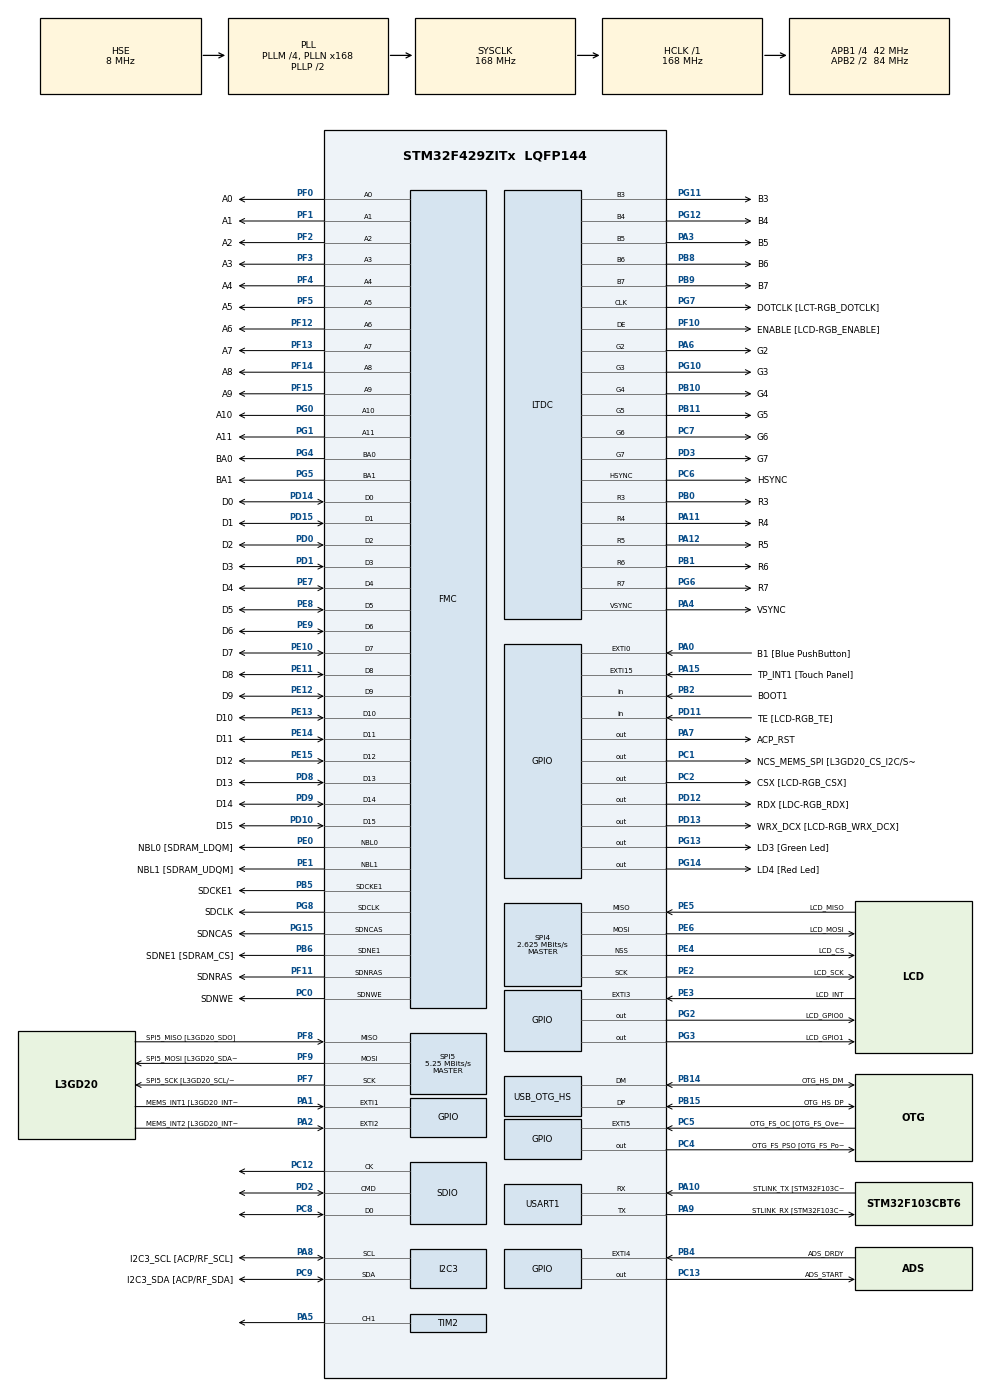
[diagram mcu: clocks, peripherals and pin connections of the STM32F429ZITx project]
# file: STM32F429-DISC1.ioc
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Dma.Request0=SDIO
Dma.Request1=SPI4_RX
Dma.Request2=SPI4_TX
Dma.SDIO.0.Direction=DMA_PERIPH_TO_MEMORY
Dma.SDIO.0.FIFOMode=DMA_FIFOMODE_ENABLE
Dma.SDIO.0.FIFOThreshold=DMA_FIFO_THRESHOLD_FULL
Dma.SDIO.0.Instance=DMA2_Stream3
Dma.SDIO.0.MemBurst=DMA_MBURST_INC4
Dma.SDIO.0.MemDataAlignment=DMA_MDATAALIGN_WORD
Dma.SDIO.0.MemInc=DMA_MINC_ENABLE
Dma.SDIO.0.Mode=DMA_PFCTRL
Dma.SDIO.0.PeriphBurst=DMA_PBURST_INC4
Dma.SDIO.0.PeriphDataAlignment=DMA_PDATAALIGN_WORD
Dma.SDIO.0.PeriphInc=DMA_PINC_DISABLE
Dma.SDIO.0.Priority=DMA_PRIORITY_VERY_HIGH
Dma.SPI4_RX.1.Direction=DMA_PERIPH_TO_MEMORY
Dma.SPI4_RX.1.FIFOMode=DMA_FIFOMODE_DISABLE
Dma.SPI4_RX.1.Instance=DMA2_Stream0
Dma.SPI4_RX.1.MemDataAlignment=DMA_MDATAALIGN_BYTE
Dma.SPI4_RX.1.MemInc=DMA_MINC_ENABLE
Dma.SPI4_RX.1.Mode=DMA_NORMAL
Dma.SPI4_RX.1.PeriphDataAlignment=DMA_PDATAALIGN_BYTE
Dma.SPI4_RX.1.PeriphInc=DMA_PINC_DISABLE
Dma.SPI4_RX.1.Priority=DMA_PRIORITY_HIGH
Dma.SPI4_TX.2.Direction=DMA_MEMORY_TO_PERIPH
Dma.SPI4_TX.2.FIFOMode=DMA_FIFOMODE_DISABLE
Dma.SPI4_TX.2.Instance=DMA2_Stream1
Dma.SPI4_TX.2.MemDataAlignment=DMA_MDATAALIGN_BYTE
Dma.SPI4_TX.2.MemInc=DMA_MINC_ENABLE
Dma.SPI4_TX.2.Mode=DMA_NORMAL
Dma.SPI4_TX.2.PeriphDataAlignment=DMA_PDATAALIGN_BYTE
Dma.SPI4_TX.2.PeriphInc=DMA_PINC_DISABLE
Dma.SPI4_TX.2.Priority=DMA_PRIORITY_LOW
FATFS.USE_DMA_CODE_SD=0
FATFS._MAX_LFN=32
FATFS._MAX_SS=4096
FATFS._USE_CHMOD=1
FATFS._USE_EXPAND=1
FMC.CASLatency1=FMC_SDRAM_CAS_LATENCY_3
FMC.ExitSelfRefreshDelay1=7
FMC.LoadToActiveDelay1=2
FMC.RCDDelay1=2
FMC.RPDelay1=2
FMC.RPDelay2=2
FMC.ReadBurst1=FMC_SDRAM_RBURST_DISABLE
FMC.ReadPipeDelay1=FMC_SDRAM_RPIPE_DELAY_1
FMC.ReadPipeDelay2=FMC_SDRAM_RPIPE_DELAY_1
FMC.RowCycleDelay1=7
FMC.RowCycleDelay2=7
FMC.SDClockPeriod1=FMC_SDRAM_CLOCK_PERIOD_2
FMC.SDClockPeriod2=FMC_SDRAM_CLOCK_PERIOD_2
FMC.SelfRefreshTime1=4
FMC.WriteRecoveryTime1=3
LTDC.ActiveH=320
LTDC.ActiveW=240
LTDC.Alpha_L0=255
LTDC.BlendingFactor1_L0=LTDC_BLENDING_FACTOR1_PAxCA
LTDC.BlendingFactor2_L0=LTDC_BLENDING_FACTOR2_PAxCA
LTDC.FBStartAdress_L0=0xD0000000
LTDC.HBP=20
LTDC.HFP=10
LTDC.HSync=10
LTDC.ImageHeight_L0=320
LTDC.ImageWidth_L0=240
LTDC.Layers=0
LTDC.PixelFormat_L0=LTDC_PIXEL_FORMAT_RGB565
LTDC.VFP=4
LTDC.VSync=2
LTDC.WindowX1_L0=240
LTDC.WindowY1_L0=320
Mcu.Family=STM32F4
Mcu.Name=STM32F429ZITx
Mcu.Package=LQFP144
NVIC.DMA2D_IRQn=true\:5\:0\:true\:false\:true\:true\:true\:true
NVIC.DMA2_Stream0_IRQn=true\:0\:0\:false\:false\:true\:false\:true\:true
NVIC.DMA2_Stream1_IRQn=true\:0\:0\:false\:false\:true\:false\:true\:true
NVIC.DMA2_Stream3_IRQn=true\:0\:0\:false\:false\:true\:false\:true\:true
NVIC.LTDC_IRQn=true\:5\:0\:true\:false\:true\:true\:true\:true
NVIC.OTG_HS_IRQn=true\:0\:0\:false\:false\:true\:true\:true\:true
NVIC.PriorityGroup=NVIC_PRIORITYGROUP_4
NVIC.SDIO_IRQn=true\:0\:0\:false\:false\:true\:true\:true\:true
NVIC.TIM1_TRG_COM_TIM11_IRQn=true\:0\:0\:false\:false\:true\:true\:true\:true
NVIC.TIM1_UP_TIM10_IRQn=true\:0\:0\:false\:false\:true\:true\:true\:true
PA0/WKUP.GPIO_Label=B1 [Blue PushButton]
PA0/WKUP.GPIO_ModeDefaultEXTI=GPIO_MODE_EVT_RISING
PA0/WKUP.GPIO_PuPd=GPIO_NOPULL
PA0/WKUP.Signal=GPXTI0
PA1.GPIO_Label=MEMS_INT1 [L3GD20_INT1]
PA1.GPIO_ModeDefaultEXTI=GPIO_MODE_EVT_RISING
PA1.GPIO_PuPd=GPIO_NOPULL
PA1.Signal=GPXTI1
PA10.GPIO_Label=STLINK_TX [STM32F103CBT6_PA2]
PA10.Mode=Asynchronous
PA10.Signal=USART1_RX
PA11.GPIO_Label=R4
PA11.GPIO_Mode=GPIO_MODE_AF_PP
PA11.GPIO_PuPd=GPIO_NOPULL
PA11.GPIO_Speed=GPIO_SPEED_FREQ_LOW
PA11.Mode=RGB565
PA11.Signal=LTDC_R4
PA12.GPIO_Label=R5
PA12.GPIO_Mode=GPIO_MODE_AF_PP
PA12.GPIO_PuPd=GPIO_NOPULL
PA12.GPIO_Speed=GPIO_SPEED_FREQ_LOW
PA12.Mode=RGB565
PA12.Signal=LTDC_R5
PA13.GPIO_Label=SWDIO
PA13.Mode=Serial_Wire
PA13.Signal=SYS_JTMS-SWDIO
PA14.GPIO_Label=SWCLK
PA14.Mode=Serial_Wire
PA14.Signal=SYS_JTCK-SWCLK
PA15.GPIO_Label=TP_INT1 [Touch Panel]
PA15.GPIO_ModeDefaultEXTI=GPIO_MODE_EVT_RISING
PA15.GPIO_PuPd=GPIO_NOPULL
PA15.Signal=GPXTI15
PA2.GPIO_Label=MEMS_INT2 [L3GD20_INT2]
PA2.GPIO_ModeDefaultEXTI=GPIO_MODE_EVT_RISING
PA2.GPIO_PuPd=GPIO_NOPULL
PA2.Signal=GPXTI2
PA3.GPIO_Label=B5
PA3.GPIO_Mode=GPIO_MODE_AF_PP
PA3.GPIO_PuPd=GPIO_NOPULL
PA3.GPIO_Speed=GPIO_SPEED_FREQ_LOW
PA3.Mode=RGB565
PA3.Signal=LTDC_B5
PA4.GPIO_Label=VSYNC
PA4.GPIO_Mode=GPIO_MODE_AF_PP
PA4.GPIO_PuPd=GPIO_NOPULL
PA4.GPIO_Speed=GPIO_SPEED_FREQ_LOW
PA4.Mode=RGB565
PA4.Signal=LTDC_VSYNC
PA5.Signal=S_TIM2_CH1_ETR
PA6.GPIO_Label=G2
PA6.GPIO_Mode=GPIO_MODE_AF_PP
PA6.GPIO_PuPd=GPIO_NOPULL
PA6.GPIO_Speed=GPIO_SPEED_FREQ_LOW
PA6.Mode=RGB565
PA6.Signal=LTDC_G2
PA7.GPIO_Label=ACP_RST
PA7.GPIO_Mode=GPIO_MODE_OUTPUT_PP
PA7.GPIO_PuPd=GPIO_NOPULL
PA7.GPIO_Speed=GPIO_SPEED_FREQ_LOW
PA7.Signal=GPIO_Output
PA8.GPIO_Label=I2C3_SCL [ACP/RF_SCL]
PA8.GPIO_Mode=GPIO_MODE_AF_OD
PA8.GPIO_Pu=GPIO_PULLUP
PA8.GPIO_PuPd=GPIO_NOPULL
PA8.GPIO_Speed=GPIO_SPEED_FREQ_LOW
PA8.Mode=I2C
PA8.Signal=I2C3_SCL
PA9.GPIO_Label=STLINK_RX [STM32F103CBT6_PA3]
PA9.Mode=Asynchronous
PA9.Signal=USART1_TX
PB0.GPIO_Label=R3
PB0.GPIO_Mode=GPIO_MODE_AF_PP
PB0.GPIO_PuPd=GPIO_NOPULL
PB0.GPIO_Speed=GPIO_SPEED_FREQ_LOW
PB0.Mode=RGB565
PB0.Signal=LTDC_R3
PB1.GPIO_Label=R6
PB1.GPIO_Mode=GPIO_MODE_AF_PP
PB1.GPIO_PuPd=GPIO_NOPULL
PB1.GPIO_Speed=GPIO_SPEED_FREQ_LOW
PB1.Mode=RGB565
PB1.Signal=LTDC_R6
PB10.GPIO_Label=G4
PB10.GPIO_Mode=GPIO_MODE_AF_PP
PB10.GPIO_PuPd=GPIO_NOPULL
PB10.GPIO_Speed=GPIO_SPEED_FREQ_LOW
PB10.Mode=RGB565
PB10.Signal=LTDC_G4
PB11.GPIO_Label=G5
PB11.GPIO_Mode=GPIO_MODE_AF_PP
PB11.GPIO_PuPd=GPIO_NOPULL
PB11.GPIO_Speed=GPIO_SPEED_FREQ_LOW
PB11.Mode=RGB565
PB11.Signal=LTDC_G5
PB12.GPIO_Label=OTG_HS_ID
PB12.GPIO_Mode=GPIO_MODE_AF_PP
PB12.GPIO_PuPd=GPIO_NOPULL
PB12.GPIO_Speed=GPIO_SPEED_FREQ_LOW
PB12.Signal=USB_OTG_HS_ID
PB13.GPIO_Label=VBUS_HS
PB13.GPIO_Mode=GPIO_MODE_INPUT
PB13.GPIO_PuPd=GPIO_NOPULL
PB13.Signal=USB_OTG_HS_VBUS
PB14.GPIO_Label=OTG_HS_DM
PB14.GPIO_Mode=GPIO_MODE_AF_PP
PB14.GPIO_PuPd=GPIO_NOPULL
PB14.GPIO_Speed=GPIO_SPEED_FREQ_LOW
PB14.Mode=Device_Only_FS
PB14.Signal=USB_OTG_HS_DM
PB15.GPIO_Label=OTG_HS_DP
PB15.GPIO_Mode=GPIO_MODE_AF_PP
PB15.GPIO_PuPd=GPIO_NOPULL
PB15.GPIO_Speed=GPIO_SPEED_FREQ_LOW
PB15.Mode=Device_Only_FS
PB15.Signal=USB_OTG_HS_DP
PB2/BOOT1.GPIO_Label=BOOT1
PB2/BOOT1.GPIO_Mode=GPIO_MODE_INPUT
PB2/BOOT1.GPIO_PuPd=GPIO_NOPULL
PB2/BOOT1.Signal=GPIO_Input
PB4.GPIO_Label=ADS_DRDY
PB4.GPIO_ModeDefaultEXTI=GPIO_MODE_IT_FALLING
PB4.GPIO_PuPd=GPIO_PULLUP
PB4.Signal=GPXTI4
PB5.GPIO_Label=SDCKE1
PB5.GPIO_Mode=GPIO_MODE_AF_PP
PB5.GPIO_PuPd=GPIO_NOPULL
PB5.GPIO_Speed=GPIO_SPEED_FREQ_VERY_HIGH
PB5.Mode=SdramChipSelect2_1
PB5.Signal=FMC_SDCKE1
PB6.GPIO_Label=SDNE1 [SDRAM_CS]
PB6.GPIO_Mode=GPIO_MODE_AF_PP
PB6.GPIO_PuPd=GPIO_NOPULL
PB6.GPIO_Speed=GPIO_SPEED_FREQ_VERY_HIGH
PB6.Mode=SdramChipSelect2_1
PB6.Signal=FMC_SDNE1
PB8.GPIO_Label=B6
PB8.GPIO_Mode=GPIO_MODE_AF_PP
PB8.GPIO_PuPd=GPIO_NOPULL
PB8.GPIO_Speed=GPIO_SPEED_FREQ_LOW
PB8.Mode=RGB565
PB8.Signal=LTDC_B6
PB9.GPIO_Label=B7
PB9.GPIO_Mode=GPIO_MODE_AF_PP
PB9.GPIO_PuPd=GPIO_NOPULL
PB9.GPIO_Speed=GPIO_SPEED_FREQ_LOW
PB9.Mode=RGB565
PB9.Signal=LTDC_B7
PC0.GPIO_Label=SDNWE
PC0.GPIO_Mode=GPIO_MODE_AF_PP
PC0.GPIO_PuPd=GPIO_NOPULL
PC0.GPIO_Speed=GPIO_SPEED_FREQ_VERY_HIGH
PC0.Signal=FMC_SDNWE
PC1.GPIO_Label=NCS_MEMS_SPI [L3GD20_CS_I2C/SPI]
PC1.GPIO_Mode=GPIO_MODE_OUTPUT_PP
PC1.GPIO_PuPd=GPIO_NOPULL
PC1.GPIO_Speed=GPIO_SPEED_FREQ_LOW
PC1.Signal=GPIO_Output
PC10.GPIO_Label=R2
PC10.GPIO_Mode=GPIO_MODE_AF_PP
PC10.GPIO_PuPd=GPIO_NOPULL
PC10.GPIO_Speed=GPIO_SPEED_FREQ_LOW
PC10.Signal=LTDC_R2
PC12.Mode=SD_1_bit
PC12.Signal=SDIO_CK
PC13.GPIO_Label=ADS_START
PC13.GPIO_Speed=GPIO_SPEED_FREQ_LOW
PC13.Signal=GPIO_Output
PC14/OSC32_IN.GPIO_Label=PC14-OSC32_IN
PC14/OSC32_IN.Mode=LSE-External-Oscillator
PC14/OSC32_IN.Signal=RCC_OSC32_IN
PC15/OSC32_OUT.GPIO_Label=PC15-OSC32_OUT
PC15/OSC32_OUT.Mode=LSE-External-Oscillator
PC15/OSC32_OUT.Signal=RCC_OSC32_OUT
PC2.GPIO_Label=CSX [LCD-RGB_CSX]
PC2.GPIO_Mode=GPIO_MODE_OUTPUT_PP
PC2.GPIO_PuPd=GPIO_NOPULL
PC2.GPIO_Speed=GPIO_SPEED_FREQ_LOW
PC2.Signal=GPIO_Output
PC4.GPIO_Label=OTG_FS_PSO [OTG_FS_PowerSwitchOn]
PC4.GPIO_Mode=GPIO_MODE_OUTPUT_PP
PC4.GPIO_PuPd=GPIO_NOPULL
PC4.GPIO_Speed=GPIO_SPEED_FREQ_LOW
PC4.Signal=GPIO_Output
PC5.GPIO_Label=OTG_FS_OC [OTG_FS_OverCurrent]
PC5.GPIO_ModeDefaultEXTI=GPIO_MODE_EVT_RISING
PC5.Signal=GPXTI5
PC6.GPIO_Label=HSYNC
PC6.GPIO_Mode=GPIO_MODE_AF_PP
PC6.GPIO_PuPd=GPIO_NOPULL
PC6.GPIO_Speed=GPIO_SPEED_FREQ_LOW
PC6.Mode=RGB565
PC6.Signal=LTDC_HSYNC
PC7.GPIO_Label=G6
PC7.GPIO_Mode=GPIO_MODE_AF_PP
PC7.GPIO_PuPd=GPIO_NOPULL
PC7.GPIO_Speed=GPIO_SPEED_FREQ_LOW
PC7.Mode=RGB565
PC7.Signal=LTDC_G6
PC8.Mode=SD_1_bit
PC8.Signal=SDIO_D0
PC9.GPIO_Label=I2C3_SDA [ACP/RF_SDA]
PC9.GPIO_Mode=GPIO_MODE_AF_OD
PC9.GPIO_Pu=GPIO_PULLUP
PC9.GPIO_PuPd=GPIO_NOPULL
PC9.GPIO_Speed=GPIO_SPEED_FREQ_LOW
PC9.Mode=I2C
PC9.Signal=I2C3_SDA
PD0.GPIO_Label=D2
PD0.GPIO_Mode=GPIO_MODE_AF_PP
PD0.GPIO_PuPd=GPIO_NOPULL
PD0.GPIO_Speed=GPIO_SPEED_FREQ_VERY_HIGH
PD0.Signal=FMC_D2_DA2
PD1.GPIO_Label=D3
PD1.GPIO_Mode=GPIO_MODE_AF_PP
PD1.GPIO_PuPd=GPIO_NOPULL
PD1.GPIO_Speed=GPIO_SPEED_FREQ_VERY_HIGH
PD1.Signal=FMC_D3_DA3
PD10.GPIO_Label=D15
PD10.GPIO_Mode=GPIO_MODE_AF_PP
PD10.GPIO_PuPd=GPIO_NOPULL
PD10.GPIO_Speed=GPIO_SPEED_FREQ_VERY_HIGH
PD10.Signal=FMC_D15_DA15
PD11.GPIO_Label=TE [LCD-RGB_TE]
PD11.GPIO_Mode=GPIO_MODE_INPUT
PD11.GPIO_PuPd=GPIO_NOPULL
PD11.Signal=GPIO_Input
PD12.GPIO_Label=RDX [LDC-RGB_RDX]
PD12.GPIO_Mode=GPIO_MODE_OUTPUT_PP
PD12.GPIO_PuPd=GPIO_NOPULL
PD12.GPIO_Speed=GPIO_SPEED_FREQ_LOW
PD12.Signal=GPIO_Output
PD13.GPIO_Label=WRX_DCX [LCD-RGB_WRX_DCX]
PD13.GPIO_Mode=GPIO_MODE_OUTPUT_PP
PD13.GPIO_PuPd=GPIO_NOPULL
PD13.GPIO_Speed=GPIO_SPEED_FREQ_LOW
PD13.Signal=GPIO_Output
PD14.GPIO_Label=D0
PD14.GPIO_Mode=GPIO_MODE_AF_PP
PD14.GPIO_PuPd=GPIO_NOPULL
PD14.GPIO_Speed=GPIO_SPEED_FREQ_VERY_HIGH
PD14.Signal=FMC_D0_DA0
PD15.GPIO_Label=D1
PD15.GPIO_Mode=GPIO_MODE_AF_PP
PD15.GPIO_PuPd=GPIO_NOPULL
PD15.GPIO_Speed=GPIO_SPEED_FREQ_VERY_HIGH
PD15.Signal=FMC_D1_DA1
PD2.Mode=SD_1_bit
PD2.Signal=SDIO_CMD
PD3.GPIO_Label=G7
PD3.GPIO_Mode=GPIO_MODE_AF_PP
PD3.GPIO_PuPd=GPIO_NOPULL
PD3.GPIO_Speed=GPIO_SPEED_FREQ_LOW
PD3.Mode=RGB565
PD3.Signal=LTDC_G7
PD6.GPIO_Label=B2
PD6.GPIO_Mode=GPIO_MODE_AF_PP
PD6.GPIO_PuPd=GPIO_NOPULL
PD6.GPIO_Speed=GPIO_SPEED_FREQ_LOW
PD6.Signal=LTDC_B2
PD8.GPIO_Label=D13
PD8.GPIO_Mode=GPIO_MODE_AF_PP
PD8.GPIO_PuPd=GPIO_NOPULL
PD8.GPIO_Speed=GPIO_SPEED_FREQ_VERY_HIGH
PD8.Signal=FMC_D13_DA13
PD9.GPIO_Label=D14
PD9.GPIO_Mode=GPIO_MODE_AF_PP
PD9.GPIO_PuPd=GPIO_NOPULL
PD9.GPIO_Speed=GPIO_SPEED_FREQ_VERY_HIGH
PD9.Signal=FMC_D14_DA14
PE0.GPIO_Label=NBL0 [SDRAM_LDQM]
PE0.GPIO_Mode=GPIO_MODE_AF_PP
PE0.GPIO_PuPd=GPIO_NOPULL
PE0.GPIO_Speed=GPIO_SPEED_FREQ_VERY_HIGH
PE0.Signal=FMC_NBL0
PE1.GPIO_Label=NBL1 [SDRAM_UDQM]
PE1.GPIO_Mode=GPIO_MODE_AF_PP
PE1.GPIO_PuPd=GPIO_NOPULL
PE1.GPIO_Speed=GPIO_SPEED_FREQ_VERY_HIGH
PE1.Signal=FMC_NBL1
PE10.GPIO_Label=D7
PE10.GPIO_Mode=GPIO_MODE_AF_PP
PE10.GPIO_PuPd=GPIO_NOPULL
PE10.GPIO_Speed=GPIO_SPEED_FREQ_VERY_HIGH
PE10.Signal=FMC_D7_DA7
PE11.GPIO_Label=D8
PE11.GPIO_Mode=GPIO_MODE_AF_PP
PE11.GPIO_PuPd=GPIO_NOPULL
PE11.GPIO_Speed=GPIO_SPEED_FREQ_VERY_HIGH
PE11.Signal=FMC_D8_DA8
PE12.GPIO_Label=D9
PE12.GPIO_Mode=GPIO_MODE_AF_PP
PE12.GPIO_PuPd=GPIO_NOPULL
PE12.GPIO_Speed=GPIO_SPEED_FREQ_VERY_HIGH
PE12.Signal=FMC_D9_DA9
PE13.GPIO_Label=D10
PE13.GPIO_Mode=GPIO_MODE_AF_PP
PE13.GPIO_PuPd=GPIO_NOPULL
PE13.GPIO_Speed=GPIO_SPEED_FREQ_VERY_HIGH
PE13.Signal=FMC_D10_DA10
PE14.GPIO_Label=D11
PE14.GPIO_Mode=GPIO_MODE_AF_PP
PE14.GPIO_PuPd=GPIO_NOPULL
PE14.GPIO_Speed=GPIO_SPEED_FREQ_VERY_HIGH
PE14.Signal=FMC_D11_DA11
PE15.GPIO_Label=D12
PE15.GPIO_Mode=GPIO_MODE_AF_PP
PE15.GPIO_PuPd=GPIO_NOPULL
PE15.GPIO_Speed=GPIO_SPEED_FREQ_VERY_HIGH
PE15.Signal=FMC_D12_DA12
PE2.GPIO_Label=LCD_SCK
PE2.Mode=Full_Duplex_Master
PE2.Signal=SPI4_SCK
PE3.GPIO_Label=LCD_INT
PE3.Signal=GPXTI3
PE4.GPIO_Label=LCD_CS
PE4.Mode=NSS_Signal_Hard_Output
PE4.Signal=SPI4_NSS
PE5.GPIO_Label=LCD_MISO
PE5.Mode=Full_Duplex_Master
PE5.Signal=SPI4_MISO
PE6.GPIO_Label=LCD_MOSI
PE6.Mode=Full_Duplex_Master
PE6.Signal=SPI4_MOSI
PE7.GPIO_Label=D4
PE7.GPIO_Mode=GPIO_MODE_AF_PP
PE7.GPIO_PuPd=GPIO_NOPULL
PE7.GPIO_Speed=GPIO_SPEED_FREQ_VERY_HIGH
PE7.Signal=FMC_D4_DA4
PE8.GPIO_Label=D5
PE8.GPIO_Mode=GPIO_MODE_AF_PP
PE8.GPIO_PuPd=GPIO_NOPULL
PE8.GPIO_Speed=GPIO_SPEED_FREQ_VERY_HIGH
PE8.Signal=FMC_D5_DA5
PE9.GPIO_Label=D6
PE9.GPIO_Mode=GPIO_MODE_AF_PP
PE9.GPIO_PuPd=GPIO_NOPULL
PE9.GPIO_Speed=GPIO_SPEED_FREQ_VERY_HIGH
PE9.Signal=FMC_D6_DA6
PF0.GPIO_Label=A0
PF0.GPIO_Mode=GPIO_MODE_AF_PP
PF0.GPIO_PuPd=GPIO_NOPULL
PF0.GPIO_Speed=GPIO_SPEED_FREQ_VERY_HIGH
PF0.Signal=FMC_A0
PF1.GPIO_Label=A1
PF1.GPIO_Mode=GPIO_MODE_AF_PP
PF1.GPIO_PuPd=GPIO_NOPULL
PF1.GPIO_Speed=GPIO_SPEED_FREQ_VERY_HIGH
PF1.Signal=FMC_A1
PF10.GPIO_Label=ENABLE [LCD-RGB_ENABLE]
PF10.GPIO_Mode=GPIO_MODE_AF_PP
PF10.GPIO_PuPd=GPIO_NOPULL
PF10.GPIO_Speed=GPIO_SPEED_FREQ_LOW
PF10.Mode=RGB565
PF10.Signal=LTDC_DE
PF11.GPIO_Label=SDNRAS
PF11.GPIO_Mode=GPIO_MODE_AF_PP
PF11.GPIO_PuPd=GPIO_NOPULL
PF11.GPIO_Speed=GPIO_SPEED_FREQ_VERY_HIGH
PF11.Signal=FMC_SDNRAS
PF12.GPIO_Label=A6
PF12.GPIO_Mode=GPIO_MODE_AF_PP
PF12.GPIO_PuPd=GPIO_NOPULL
PF12.GPIO_Speed=GPIO_SPEED_FREQ_VERY_HIGH
PF12.Signal=FMC_A6
PF13.GPIO_Label=A7
PF13.GPIO_Mode=GPIO_MODE_AF_PP
PF13.GPIO_PuPd=GPIO_NOPULL
PF13.GPIO_Speed=GPIO_SPEED_FREQ_VERY_HIGH
PF13.Signal=FMC_A7
PF14.GPIO_Label=A8
PF14.GPIO_Mode=GPIO_MODE_AF_PP
PF14.GPIO_PuPd=GPIO_NOPULL
PF14.GPIO_Speed=GPIO_SPEED_FREQ_VERY_HIGH
PF14.Signal=FMC_A8
PF15.GPIO_Label=A9
PF15.GPIO_Mode=GPIO_MODE_AF_PP
PF15.GPIO_PuPd=GPIO_NOPULL
PF15.GPIO_Speed=GPIO_SPEED_FREQ_VERY_HIGH
PF15.Signal=FMC_A9
PF2.GPIO_Label=A2
PF2.GPIO_Mode=GPIO_MODE_AF_PP
PF2.GPIO_PuPd=GPIO_NOPULL
PF2.GPIO_Speed=GPIO_SPEED_FREQ_VERY_HIGH
PF2.Signal=FMC_A2
PF3.GPIO_Label=A3
PF3.GPIO_Mode=GPIO_MODE_AF_PP
PF3.GPIO_PuPd=GPIO_NOPULL
PF3.GPIO_Speed=GPIO_SPEED_FREQ_VERY_HIGH
PF3.Signal=FMC_A3
PF4.GPIO_Label=A4
PF4.GPIO_Mode=GPIO_MODE_AF_PP
PF4.GPIO_PuPd=GPIO_NOPULL
PF4.GPIO_Speed=GPIO_SPEED_FREQ_VERY_HIGH
PF4.Signal=FMC_A4
PF5.GPIO_Label=A5
PF5.GPIO_Mode=GPIO_MODE_AF_PP
PF5.GPIO_PuPd=GPIO_NOPULL
PF5.GPIO_Speed=GPIO_SPEED_FREQ_VERY_HIGH
PF5.Signal=FMC_A5
PF7.GPIO_Label=SPI5_SCK [L3GD20_SCL/SPC]
PF7.GPIO_Mode=GPIO_MODE_AF_PP
PF7.GPIO_PuPd=GPIO_NOPULL
PF7.GPIO_Speed=GPIO_SPEED_FREQ_LOW
PF7.Mode=Full_Duplex_Master
PF7.Signal=SPI5_SCK
PF8.GPIO_Label=SPI5_MISO [L3GD20_SDO]
PF8.GPIO_Mode=GPIO_MODE_AF_PP
PF8.GPIO_PuPd=GPIO_NOPULL
PF8.GPIO_Speed=GPIO_SPEED_FREQ_LOW
PF8.Mode=Full_Duplex_Master
PF8.Signal=SPI5_MISO
PF9.GPIO_Label=SPI5_MOSI [L3GD20_SDA/SDI/SDO]
PF9.GPIO_Mode=GPIO_MODE_AF_PP
PF9.GPIO_PuPd=GPIO_NOPULL
PF9.GPIO_Speed=GPIO_SPEED_FREQ_LOW
PF9.Mode=Full_Duplex_Master
PF9.Signal=SPI5_MOSI
PG0.GPIO_Label=A10
PG0.GPIO_Mode=GPIO_MODE_AF_PP
PG0.GPIO_PuPd=GPIO_NOPULL
PG0.GPIO_Speed=GPIO_SPEED_FREQ_VERY_HIGH
PG0.Signal=FMC_A10
PG1.GPIO_Label=A11
PG1.GPIO_Mode=GPIO_MODE_AF_PP
PG1.GPIO_PuPd=GPIO_NOPULL
PG1.GPIO_Speed=GPIO_SPEED_FREQ_VERY_HIGH
PG1.Signal=FMC_A11
PG10.GPIO_Label=G3
PG10.GPIO_Mode=GPIO_MODE_AF_PP
PG10.GPIO_PuPd=GPIO_NOPULL
PG10.GPIO_Speed=GPIO_SPEED_FREQ_LOW
PG10.Mode=RGB565
PG10.Signal=LTDC_G3
PG11.GPIO_Label=B3
PG11.GPIO_Mode=GPIO_MODE_AF_PP
PG11.GPIO_PuPd=GPIO_NOPULL
PG11.GPIO_Speed=GPIO_SPEED_FREQ_LOW
PG11.Mode=RGB565
PG11.Signal=LTDC_B3
PG12.GPIO_Label=B4
PG12.GPIO_Mode=GPIO_MODE_AF_PP
PG12.GPIO_PuPd=GPIO_NOPULL
PG12.GPIO_Speed=GPIO_SPEED_FREQ_LOW
PG12.Mode=RGB565
PG12.Signal=LTDC_B4
PG13.GPIO_Label=LD3 [Green Led]
PG13.GPIO_Mode=GPIO_MODE_OUTPUT_PP
PG13.GPIO_PuPd=GPIO_NOPULL
PG13.GPIO_Speed=GPIO_SPEED_FREQ_LOW
PG13.Signal=GPIO_Output
PG14.GPIO_Label=LD4 [Red Led]
PG14.GPIO_Mode=GPIO_MODE_OUTPUT_PP
PG14.GPIO_PuPd=GPIO_NOPULL
PG14.GPIO_Speed=GPIO_SPEED_FREQ_LOW
PG14.Signal=GPIO_Output
PG15.GPIO_Label=SDNCAS
PG15.GPIO_Mode=GPIO_MODE_AF_PP
PG15.GPIO_PuPd=GPIO_NOPULL
PG15.GPIO_Speed=GPIO_SPEED_FREQ_VERY_HIGH
PG15.Signal=FMC_SDNCAS
PG2.GPIO_Label=LCD_GPIO0
PG2.GPIO_ModeDefaultOutputPP=GPIO_MODE_OUTPUT_OD
PG2.GPIO_PuPd=GPIO_PULLUP
PG2.Signal=GPIO_Output
PG3.GPIO_Label=LCD_GPIO1
PG3.GPIO_ModeDefaultOutputPP=GPIO_MODE_OUTPUT_OD
PG3.GPIO_PuPd=GPIO_PULLUP
PG3.Signal=GPIO_Output
PG4.GPIO_Label=BA0
PG4.GPIO_Mode=GPIO_MODE_AF_PP
PG4.GPIO_PuPd=GPIO_NOPULL
PG4.GPIO_Speed=GPIO_SPEED_FREQ_VERY_HIGH
PG4.Signal=FMC_A14_BA0
PG5.GPIO_Label=BA1
PG5.GPIO_Mode=GPIO_MODE_AF_PP
PG5.GPIO_PuPd=GPIO_NOPULL
PG5.GPIO_Speed=GPIO_SPEED_FREQ_VERY_HIGH
PG5.Signal=FMC_A15_BA1
PG6.GPIO_Label=R7
PG6.GPIO_Mode=GPIO_MODE_AF_PP
PG6.GPIO_PuPd=GPIO_NOPULL
PG6.GPIO_Speed=GPIO_SPEED_FREQ_LOW
PG6.Mode=RGB565
PG6.Signal=LTDC_R7
PG7.GPIO_Label=DOTCLK [LCT-RGB_DOTCLK]
PG7.GPIO_Mode=GPIO_MODE_AF_PP
PG7.GPIO_PuPd=GPIO_NOPULL
PG7.GPIO_Speed=GPIO_SPEED_FREQ_LOW
PG7.Mode=RGB565
PG7.Signal=LTDC_CLK
PG8.GPIO_Label=SDCLK
PG8.GPIO_Mode=GPIO_MODE_AF_PP
PG8.GPIO_PuPd=GPIO_NOPULL
PG8.GPIO_Speed=GPIO_SPEED_FREQ_VERY_HIGH
PG8.Signal=FMC_SDCLK
PH0/OSC_IN.GPIO_Label=PH0-OSC_IN
PH0/OSC_IN.Mode=HSE-External-Oscillator
PH0/OSC_IN.Signal=RCC_OSC_IN
PH1/OSC_OUT.GPIO_Label=PH1-OSC_OUT
PH1/OSC_OUT.Mode=HSE-External-Oscillator
PH1/OSC_OUT.Signal=RCC_OSC_OUT
ProjectManager.HeapSize=0x1000
ProjectManager.StackSize=0x2000
ProjectManager.TargetToolchain=MDK-ARM V5
RCC.48MHZClocksFreq_Value=48000000
RCC.AHBFreq_Value=168000000
RCC.APB1CLKDivider=RCC_HCLK_DIV4
RCC.APB1Freq_Value=42000000
RCC.APB1TimFreq_Value=84000000
RCC.APB2CLKDivider=RCC_HCLK_DIV2
RCC.APB2Freq_Value=84000000
RCC.APB2TimFreq_Value=168000000
RCC.CortexFreq_Value=168000000
RCC.HCLKFreq_Value=168000000
RCC.HSE_VALUE=8000000
RCC.HSI_VALUE=16000000
RCC.PLLM=4
RCC.PLLN=168
RCC.PLLQ=7
RCC.PLLSAIDivR=RCC_PLLSAIDIVR_4
RCC.PLLSAIN=100
RCC.PLLSAIR=4
RCC.RCC_RTC_Clock_Source=RCC_RTCCLKSOURCE_LSE
RCC.RCC_RTC_Clock_SourceVirtual=RCC_RTCCLKSOURCE_LSE
RCC.SYSCLKFreq_VALUE=168000000
RCC.SYSCLKSource=RCC_SYSCLKSOURCE_PLLCLK
RCC.VCOOutputFreq_Value=336000000
RTC.Date=30
RTC.Format=RTC_FORMAT_BIN
RTC.Hours=9
RTC.Minutes=6
RTC.Month=RTC_MONTH_MAY
RTC.StoreOperation=RTC_STOREOPERATION_SET
RTC.WeekDay=RTC_WEEKDAY_SUNDAY
RTC.Year=22
SDIO.ClockBypass=SDIO_CLOCK_BYPASS_DISABLE
SDIO.ClockDiv=2
SDIO.HardwareFlowControl=SDIO_HARDWARE_FLOW_CONTROL_ENABLE
SH.FMC_A0.0=FMC_A0,12b-sda1
SH.FMC_A1.0=FMC_A1,12b-sda1
SH.FMC_A10.0=FMC_A10,12b-sda1
SH.FMC_A11.0=FMC_A11,12b-sda1
SH.FMC_A14_BA0.0=FMC_BA0,FourSdramBanks1
SH.FMC_A15_BA1.0=FMC_BA1,FourSdramBanks1
SH.FMC_A2.0=FMC_A2,12b-sda1
SH.FMC_A3.0=FMC_A3,12b-sda1
SH.FMC_A4.0=FMC_A4,12b-sda1
SH.FMC_A5.0=FMC_A5,12b-sda1
SH.FMC_A6.0=FMC_A6,12b-sda1
SH.FMC_A7.0=FMC_A7,12b-sda1
SH.FMC_A8.0=FMC_A8,12b-sda1
SH.FMC_A9.0=FMC_A9,12b-sda1
SH.FMC_D0_DA0.0=FMC_D0,sd-16b-d1
SH.FMC_D10_DA10.0=FMC_D10,sd-16b-d1
SH.FMC_D11_DA11.0=FMC_D11,sd-16b-d1
SH.FMC_D12_DA12.0=FMC_D12,sd-16b-d1
SH.FMC_D13_DA13.0=FMC_D13,sd-16b-d1
SH.FMC_D14_DA14.0=FMC_D14,sd-16b-d1
SH.FMC_D15_DA15.0=FMC_D15,sd-16b-d1
SH.FMC_D1_DA1.0=FMC_D1,sd-16b-d1
SH.FMC_D2_DA2.0=FMC_D2,sd-16b-d1
SH.FMC_D3_DA3.0=FMC_D3,sd-16b-d1
SH.FMC_D4_DA4.0=FMC_D4,sd-16b-d1
SH.FMC_D5_DA5.0=FMC_D5,sd-16b-d1
SH.FMC_D6_DA6.0=FMC_D6,sd-16b-d1
SH.FMC_D7_DA7.0=FMC_D7,sd-16b-d1
SH.FMC_D8_DA8.0=FMC_D8,sd-16b-d1
SH.FMC_D9_DA9.0=FMC_D9,sd-16b-d1
SH.FMC_NBL0.0=FMC_NBL0,Sd2ByteEnable1
SH.FMC_NBL1.0=FMC_NBL1,Sd2ByteEnable1
SH.FMC_SDCLK.0=FMC_SDCLK,12b-sda1
SH.FMC_SDNCAS.0=FMC_SDNCAS,12b-sda1
SH.FMC_SDNRAS.0=FMC_SDNRAS,12b-sda1
SH.FMC_SDNWE.0=FMC_SDNWE,12b-sda1
SH.S_TIM2_CH1_ETR.0=TIM2_CH1,PWM Generation1 CH1
SPI4.BaudRatePrescaler=SPI_BAUDRATEPRESCALER_32
SPI4.CLKPhase=SPI_PHASE_2EDGE
SPI4.CalculateBaudRate=2.625 MBits/s
SPI4.Direction=SPI_DIRECTION_2LINES
SPI4.Mode=SPI_MODE_MASTER
SPI4.VirtualNSS=VM_NSSHARD
SPI4.VirtualType=VM_MASTER
SPI5.BaudRatePrescaler=SPI_BAUDRATEPRESCALER_16
SPI5.CalculateBaudRate=5.25 MBits/s
SPI5.Direction=SPI_DIRECTION_2LINES
SPI5.Mode=SPI_MODE_MASTER
SPI5.VirtualType=VM_MASTER
TIM10.Period=9999
TIM10.Prescaler=16799
TIM11.Period=999
TIM11.Prescaler=16799
TIM2.Channel-PWM\ Generation1\ CH1=TIM_CHANNEL_1
TIM2.Period=3999
TIM2.Prescaler=41999
TIM2.Pulse-PWM\ Generation1\ CH1=79
USART1.VirtualMode=VM_ASYNC
USB_DEVICE.CLASS_NAME_HS=CDC
USB_DEVICE.VirtualMode-CDC_HS=Cdc
USB_DEVICE.VirtualModeHS=Cdc_HS
USB_OTG_HS.VirtualMode-Device_Only_FS=Device_Only_FS
VP_CRC_VS_CRC.Mode=CRC_Activate
VP_DMA2D_VS_DMA2D.Mode=DMA2D_Activate
VP_FATFS_VS_SDIO.Mode=SDIO
VP_RTC_VS_RTC_Activate.Mode=RTC_Enabled
VP_RTC_VS_RTC_Calendar.Mode=RTC_Calendar
VP_TIM10_VS_ClockSourceINT.Mode=Enable_Timer
VP_TIM11_VS_ClockSourceINT.Mode=Enable_Timer
VP_USB_DEVICE_VS_USB_DEVICE_CDC_HS.Mode=CDC_HS
board=STM32F429I-DISC1

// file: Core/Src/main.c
/* USER CODE BEGIN Header */
/** new test
  ******************************************************************************
  * @file           : main.c
  * @brief          : Main program body
  ******************************************************************************
  * @attention
  *
  * Copyright (c) 2022 STMicroelectronics.
  * All rights reserved.
  *
  * This software is licensed under terms that can be found in the LICENSE file
  * in the root directory of this software component.
  * If no LICENSE file comes with this software, it is provided AS-IS.
  *
  ******************************************************************************
  */
/* USER CODE END Header */
#include "main.h"
#include "crc.h"
#include "dma.h"
#include "dma2d.h"
#include "fatfs.h"
#include "i2c.h"
#include "ltdc.h"
#include "rtc.h"
#include "sdio.h"
#include "spi.h"
#include "tim.h"
#include "usart.h"
#include "usb_device.h"
#include "gpio.h"
#include "fmc.h"

/* USER CODE BEGIN Includes */
#include "stm32f429i_discovery_lcd1.h"
#include "stm32f429i_discovery_ts.h"
#include "color2.h"
#include "save.h"
#include "stlogo.h"
#include "stdio.h"
#include "string.h"
#include <stdlib.h>
#include <math.h>
#include "arm_math.h"
#include "usbd_cdc_if.h"
/* USER CODE END Includes */

/* USER CODE BEGIN PD */
#define	rd_step1 2100;
#define	rd_step2 256;
#define	rd_step3 4200;
/* USER CODE END PD */

/* USER CODE BEGIN PV */
//ADS-----------------------------
	uint8_t tx_buff1[30] ;
	uint8_t tx_buff2[28] ;//= {0,1,2,3,4,5,6,7};
	uint8_t rx_buff[28];

	uint8_t rcv_buff[28];
	uint16_t sample_counter;        //sample counter
	uint16_t n_sample = 800;        //number of sample
	uint32_t in_signal[800];			  // input signal vector
//ADS-----------------------------
RTC_TimeTypeDef currentTime;
RTC_DateTypeDef currentDate;
RTC_TimeTypeDef sTime;
RTC_DateTypeDef sDate;
 struct  stm_packet												//34byte
		{
			uint8_t start;												//start byte	(0x55)
			uint8_t stm_com;											//command : "idel=0","get_status=1","wait for charge=2","charge_OK=3","charge_NOK=4","wait for shock=5","shock_OK=6","shock_NOK=7","...
			uint8_t stm_status;	//uint16_t stm_status;									//stm board internal status
			uint16_t date_year;										// year (binary), offset=2000
			uint8_t date_month;										// month (binary)
			uint8_t date_day;											// day (binary)
			uint8_t time_hour;										// hour (binary)
			uint8_t time_minute;									// minute (binary)
			uint8_t time_second;									// second (binary)
			uint8_t stop;													//stop byte	(0xAA)
		} s1;

struct  PcPacket{
    uint8_t     start;			//start byte
		uint8_t     CommandType;     //command : "charge = 1","shock = 2 ","sync_shock = 3 ",...
    uint8_t     status;         //PC internal status
    uint8_t     year;           // year (binary), offset=2000
    uint8_t     month;          // month (binary)
    uint8_t     day;            // day (binary)
    uint8_t     hour;           // hour (binary)
    uint8_t     minute;         // minute (binary)
    uint8_t     second;         // second (binary)
    uint8_t     stop;			//stop byte
}pc,rcv;				//228byte

 extern   struct  bit_flag
		{
			uint8_t file_end;
			uint8_t file_new_create;
			uint8_t PC_DAT_RCV	;		//flag for recieve packet form pc
			uint8_t STM_DAT_STP;
			uint8_t error_handler;
			uint8_t history ;
			uint8_t download ;
			uint8_t settime ;
			uint8_t format ;
			unsigned sampling_state :1;
			unsigned data_rcv_flg	  :1;
			unsigned data_dump_flg  :1;
			unsigned data_set_flg   :1;
			unsigned spi4_strt_flg	:1;																				// priode timer flag for transmit spi4
			unsigned spi4_end_flg 	:1;																				// priode timer flag for transmit spi4
			unsigned tim10_flg 			:1;
			unsigned tim11_flg 			:1;
		} f1 ;

  uint8_t pc_buf[228];         //data recieve buffer
	uint16_t pc_buf_size;        //number of bytes recieve size
	uint8_t num_packet = 10 ;	  //number of bytes in packet for recieve data
	uint8_t stm_buf[30]={0x55,1,2,3,4,5,6,7,8,9,10,11,12,13,14,15,16,17,18,19,20,21,22,23,24,25,26,27,254,0xAA}; //sample packet with 30 byte
	uint8_t stm_buf_DSP[32];
  static uint8_t buffer[_MAX_SS]; /* a work buffer for the f_mkfs() */

extern uint8_t SET_DATA[4];          //setting data

/* USER CODE END PV */

void SystemClock_Config(void);
/* USER CODE BEGIN PFP */
void Touchscreen_Calibration (void);
void var_print(uint16_t,uint16_t,uint16_t);
void svar_print(int32_t,uint16_t,uint16_t);
void var_printH(uint16_t,uint8_t,uint8_t,uint16_t,uint16_t);
void var8_printH(uint8_t,uint8_t,uint16_t,uint16_t);
void svar_printH(int32_t,uint8_t,uint16_t,uint16_t);
void txt_printH(uint8_t *, uint8_t, uint8_t, uint16_t, uint16_t);
void disp( char, uint8_t, uint16_t, uint16_t, char, char, char, char, char, char );
void disp1( char ,char ,char ,char ,char ,char );

void rd_disk(void);
void rd_file (void);
FRESULT scan_files ( char* path );
void make_folder(void);
void w_file_name (void);
void r_file_name (void);
void cpypc_pcbuf (void);

/* USER CODE END PFP */

/* USER CODE BEGIN 0 */
extern uint8_t retSD; /* Return value for SD */
extern FATFS SDFatFS; /* File system object for SD logical drive */
extern FIL SDFile1,SDFile2; /* File object for SD */
extern char SDPath[4]; /* SD logical drive path */
  FRESULT res;                                          /* FatFs function common result code */
  uint32_t byteswritten, bytesread;                     /* File write/read counts */
  uint8_t rtext[8400];                                  /* Read File buffer */
	uint32_t icnt ;
	uint32_t diff_dat ;
	uint32_t file_size ;
	uint16_t rd_step = rd_step1;
	char NFILE[28];   		  // file name
	char SDpat[15];					// temp path
	char str_table[20] = {0x30,0x31,0x32,0x33,0x34,0x35,0x36,0x37,0x38,0x39,0x30,0x31,0x32,0x33,0x34,0x35, 0x2E,0x42,0x49,0x4E}; // " . B I N "
  char SDpat_r[15];   		// input path buffer
	char file[8];				    // temp buffer for path files array
	char file_arr[750][8];	// path files array
	char rfile[28];					//file name for read from file
	uint16_t f_cnt = 0;			// scan found files counter
//==================================================================================

static void GetPosition(void);
static void Update_ColorSize(void);
static uint32_t radius = 1;

static char mod_flag = 0;
static char wav_flag = 0;
static char bpm_flag = 0;
static char wid_flag = 0;
static char amp_flag = 0;
static char range_flag = 0;
static char tim_flag = 0;
static char r_flag = 0;

static char MODE = 0;										// mode input    ( "0" = ECG-SIM , "1" = DEFITST ,  ECG-SIM default )
static char RANGE = 1;										// range input   ( "0" = 1.5Kv , "1" = 3.0Kv ,  4kv default )
static char TIME = 0;										// time input    ( "0" = 20ms, "1" = 40ms ,  20ms default
static char AMPL = 1;										// amplitude     ( 5 mv default )
static uint8_t CURVE_TYPE = 1;							// type of curve ( qrs default )
static uint16_t BPM = 60;								// bpm					 ( 75 bpm default )
static uint16_t WIDTH = 100;							// pulse width	 ( 500 ms default )
static float R = 50;										//load resistance
/* USER CODE END 0 */

int main(void)
{

  /* MCU Configuration--------------------------------------------------------*/

  /* Reset of all peripherals, Initializes the Flash interface and the Systick. */
  HAL_Init();

  /* Configure the system clock */
  SystemClock_Config();

  /* Initialize all configured peripherals */
  MX_GPIO_Init();
  MX_CRC_Init();
  MX_DMA2D_Init();
  MX_FMC_Init();
  MX_I2C3_Init();
  MX_LTDC_Init();
  MX_SPI5_Init();
  MX_USART1_UART_Init();
  MX_RTC_Init();
  MX_SDIO_SD_Init();
  MX_FATFS_Init();
  MX_DMA_Init();
  MX_SPI4_Init();
  MX_USB_DEVICE_Init();
  MX_TIM2_Init();
  MX_TIM10_Init();
  MX_TIM11_Init();
  /* USER CODE BEGIN 2 */
  /* Initialize the LCD */
  BSP_LCD_Init();
  /* Layer2 Init */
  BSP_LCD_LayerDefaultInit(1, LCD_FRAME_BUFFER_LAYER1);
  /* Set Foreground Layer */
  BSP_LCD_SelectLayer(1);
  /* Clear the LCD */
  BSP_LCD_Clear(LCD_COLOR_WHITE);
  BSP_LCD_SetColorKeying(1, LCD_COLOR_WHITE);
  BSP_LCD_SetLayerVisible(1, DISABLE);

  /* Layer1 Init */
  BSP_LCD_LayerDefaultInit(0, LCD_FRAME_BUFFER_LAYER0);

  /* Set Foreground Layer */
  BSP_LCD_SelectLayer(0);

  /* Enable The LCD */
  BSP_LCD_DisplayOn();

  /* Clear the LCD */
  BSP_LCD_Clear(LCD_COLOR_WHITE);

  Touchscreen_Calibration();
  BSP_TS_Init(BSP_LCD_GetXSize(), BSP_LCD_GetYSize());

//-----------------------------------------------------  /* Draw Bitmap */------------------
//BSP_LCD_DrawBitmap(40, 2, (uint8_t *)arm3);
//HAL_Delay(3000);
//-----------------------------------------------------  /* Draw Bitmap */------------------

BSP_LCD_SelectLayer(0);//select on which layer we write
BSP_LCD_DisplayOn();//turn on LCD
BSP_LCD_SetFont(&Font24);
BSP_LCD_Clear(LCD_COLOR_BLUE);//clear the LCD on blue color
BSP_LCD_SetBackColor(LCD_COLOR_BLUE);//set text background color

BSP_LCD_DisplayStringAtLineH(0," TPD Demo tester");

disp ( MODE , CURVE_TYPE , BPM , WIDTH , AMPL , mod_flag , wav_flag , bpm_flag , wid_flag , amp_flag );
BSP_LCD_SetTextColor(LCD_COLOR_WHITE);//set text color
BSP_LCD_SetBackColor(LCD_COLOR_RED);//set text background color
txt_printH("SET",3,11,200,35);
  	HAL_GPIO_WritePin(GPIOG, GPIO_PIN_13, GPIO_PIN_RESET );     //led G off
  	HAL_GPIO_WritePin(GPIOG, GPIO_PIN_14, GPIO_PIN_RESET );     //led R off
		f1.file_end = 0;
	  f1.error_handler = 0;
//mSD------------------------------------------------------------------------------------------------
	HAL_RTC_GetTime(&hrtc, &currentTime, FORMAT_BIN);
	HAL_RTC_GetDate(&hrtc, &currentDate, FORMAT_BIN);
	if(f_mount(&SDFatFS, (TCHAR const*)SDPath, 0) != FR_OK)	{								//mount disk
		Error_Handler();
	}
//	BSP_LED_On(LED3);
	make_folder();																													//making folder & directory
	w_file_name();																													//create file name from date

	if (f_open(&SDFile1, NFILE, FA_CREATE_ALWAYS | FA_WRITE ) != FR_OK) {		//open file
		Error_Handler();
	}

	if (f_lseek(&SDFile1, f_size(&SDFile1))!= FR_OK)	{											//seek addres file
		Error_Handler();
	}
	f1.file_new_create = 0;
	f1.STM_DAT_STP = 0;
//mSD------------------------------------------------------------------------------------------------
  /* USER CODE END 2 */

  /* Infinite loop */
  while (1)
  {

    /* USER CODE BEGIN 3 */
	}
//ADS----------------------------------------------------------------------------
		if ( f1.sampling_state == 1 )	{
			if	( sample_counter != n_sample )	{
				if ( f1.data_rcv_flg == 1 )  {
///////// READ DATA (9 byte)
					HAL_GPIO_WritePin(GPIOE, GPIO_PIN_4, GPIO_PIN_RESET );					//CS_P	 			active
					HAL_SPI_TransmitReceive_DMA(&hspi4,tx_buff1,rcv_buff,9);				//27 byte (216 bit)	RECIEVE
					in_signal[sample_counter] = (rcv_buff[3]<<24)+(rcv_buff[4]<<16)+(rcv_buff[5]<<8);
					f1.data_rcv_flg = 0;
///////// READ DATA (9 byte)
					sample_counter++;
				}
			}
			else	{
				sample_counter = 0;
				f1.sampling_state = 0;
			}
		}
//ADS----------------------------------------------------------------------------
//mSD----------------------------------------------------------------------------new file create
	if ( (currentTime.Minutes == 0) && (currentTime.Seconds <= 10) && (f1.file_new_create == 0) )	{
		if (f_close(&SDFile1) != FR_OK )	{
			Error_Handler();
		}
		make_folder();
		w_file_name();

		if (f_open(&SDFile1, NFILE, FA_CREATE_ALWAYS | FA_WRITE ) != FR_OK) {
			Error_Handler();
		}

		if (f_lseek(&SDFile1, f_size(&SDFile1))!= FR_OK)	{
			Error_Handler();
		}
		f1.file_new_create = 1;
	}else	if ( (currentTime.Minutes == 0) && (currentTime.Seconds > 10) ) {
		f1.file_new_create = 0;
	}
//mSD----------------------------------------------------------------------------
//DSP---------------------------------------------------
//										if ( f1.data_dump_flg == 0 ) {
//												CDC_Transmit_HS(stm_buf_DSP,6);
//										}
										else	{}
//mSD write------------------------------------------------------------------
		res = f_write(&SDFile1, stm_buf_DSP, 6 , (void *)&byteswritten);
		if((byteswritten == 0) || (res != FR_OK)) {
			Error_Handler();
		}
		res = f_sync(&SDFile1);
		if( res != FR_OK )	{
			Error_Handler();
		}
//mSD write------------------------------------------------------------------

//DSP---------------------------------------------------

//RTC------------------------------------------------------------------------------------------------
	if	( HAL_GPIO_ReadPin( GPIOA, GPIO_PIN_0 ) == 1 	)	{		//Blue push botton press
				sTime.Hours = 17;
				sTime.Minutes = 17;
				sTime.Seconds = 0;
				sTime.DayLightSaving = RTC_DAYLIGHTSAVING_NONE;
				sTime.StoreOperation = RTC_STOREOPERATION_SET;
				if (HAL_RTC_SetTime(&hrtc, &sTime, RTC_FORMAT_BIN) != HAL_OK)	{
					Error_Handler();
				}
				sDate.WeekDay = RTC_WEEKDAY_SATURDAY;
				sDate.Month = 12;
				sDate.Date = 9;
				sDate.Year = 22;
				if (HAL_RTC_SetDate(&hrtc, &sDate, RTC_FORMAT_BIN) != HAL_OK) {
					Error_Handler();
				}
				HAL_RTCEx_BKUPWrite(&hrtc,RTC_BKP_DR0,0x32F2);
			}
//RTC------------------------------------------------------------------------------------------------

//PC Request-----------------------------------------------------------------------------------------
	if (f1.PC_DAT_RCV == 1)		{

		if ( pc_buf[0] == 0x55 && pc_buf[9] == 0xAA )	{
			cpypc_pcbuf();																			// load "pc_buff to "pc structure"

//---------------------------------
			if (pc.CommandType == 0x01)	{																						//setting signal
				f1.download = 1;
			}

//---------------------------------
			if (pc.CommandType == 0x02)	{																						//set time
				f1.settime = 1;
				HAL_TIM_Base_Stop_IT(&htim10);																		//timer stop blink G led
				htim10.Init.Period = 3000;
				HAL_TIM_Base_Init(&htim10);
				HAL_TIM_Base_Start_IT(&htim10);																		//timer start blink G led
				sTime.Hours = pc.hour;
				sTime.Minutes = pc.minute;
				sTime.Seconds = pc.second;
				sTime.DayLightSaving = RTC_DAYLIGHTSAVING_NONE;
				sTime.StoreOperation = RTC_STOREOPERATION_SET;
				if (HAL_RTC_SetTime(&hrtc, &sTime, RTC_FORMAT_BIN) != HAL_OK)	{
					Error_Handler();
				}
				sDate.WeekDay = RTC_WEEKDAY_SATURDAY;
				sDate.Month = pc.month;
				sDate.Date = pc.day;
				sDate.Year = pc.year;
				if (HAL_RTC_SetDate(&hrtc, &sDate, RTC_FORMAT_BIN) != HAL_OK) {
					Error_Handler();
				}
				HAL_RTCEx_BKUPWrite(&hrtc,RTC_BKP_DR0,0x32F2);
				HAL_TIM_Base_Stop_IT(&htim10);																		//timer stop blink G led
				htim10.Init.Period = 9999;
				HAL_TIM_Base_Init(&htim10);
				HAL_TIM_Base_Start_IT(&htim10);																		//timer start blink G led
				f1.settime = 0;
			}

//---------------------------------
			if (pc.CommandType == 0x03)	{																						//format SD DISK
				f1.format = 1;
				htim10.Init.Period = 5000;
				HAL_TIM_Base_Init(&htim10);
				HAL_TIM_Base_Start_IT(&htim10);																		//timer start blink G led
				if(f_mkfs((TCHAR const*)SDPath, 0, 0, buffer, sizeof(buffer)) != FR_OK)	{		/* FatFs Format  */
						Error_Handler();
				}
				HAL_Delay(10000);																			//10s delay
				if(FATFS_LinkDriver(&SD_Driver, SDPath) != FR_OK)	{  /*Register the file system object to the FatFs module*/
					Error_Handler();
				}
				HAL_Delay(1000);																			//1s delay
				if(f_mount(&SDFatFS, (TCHAR const*)SDPath, 0) != FR_OK)	{		/*mount disk*/
					Error_Handler();
				}

				make_folder();																							/*making folder & directory*/
				w_file_name();																							/*create file name from date*/

				if (f_open(&SDFile1, NFILE, FA_CREATE_ALWAYS | FA_WRITE ) != FR_OK) {		/*open file*/
					Error_Handler();
				}

				if (f_lseek(&SDFile1, f_size(&SDFile1))!= FR_OK)	{					/*seek addres file*/
					Error_Handler();
				}
				htim10.Init.Period = 9999;
				HAL_TIM_Base_Init(&htim10);
				HAL_TIM_Base_Start_IT(&htim10);																		//timer start blink G led
				f1.file_new_create = 0;
				f1.format = 0;
			}
//---------------------------------
			if (pc.CommandType == 0x04)	{																						//history reguest
				f1.history = 1;
				htim10.Init.Period = 1000;
				HAL_TIM_Base_Init(&htim10);
				HAL_TIM_Base_Start_IT(&htim10);																		//timer start blink N led

				SDpat_r[0] = 0x2F;        											 //  "/"
				if ( pc.year <= currentDate.Year ) {
					SDpat_r[1] = 0x32;             //ascii "2"
					SDpat_r[2] = 0x30;             //ascii "0"
					SDpat_r[3] = str_table[(pc.year /10)];
					SDpat_r[4] = str_table[(pc.year %10)];
					if ( pc.month <= 12 && pc.month != 0 )	{
						SDpat_r[5] = 0x2F;        										//  "/"
						SDpat_r[6] = str_table[( pc.month /10 )];
						SDpat_r[7] = str_table[( pc.month %10 )];
						if ( pc.day <= 31 && pc.day != 0 )	{
							SDpat_r[8] = 0x2F;        									//  "/"
							SDpat_r[9] = str_table[( pc.day /10 )];
							SDpat_r[10] = str_table[( pc.day %10 )];
							if ( pc.hour <= 23 ) {
								SDpat_r[11] = 0x2F;       							  //  "/"
								SDpat_r[12] = str_table[( pc.hour /10 )];
								SDpat_r[13] = str_table[( pc.hour %10 )];
								SDpat_r[14] = 0x00;       							  //  "0"
							}else	{
								SDpat_r[11] = 0x00;        //  "0"
								SDpat_r[12] = 0x00;        //  "0"
								SDpat_r[13] = 0x00;        //  "0"
								SDpat_r[14] = 0x00;        //  "0"
							}
						}else	{
							SDpat_r[8] = 0x00;         //  "0"
							SDpat_r[9] = 0x00;         //  "0"
							SDpat_r[10] = 0x00;        //  "0"
							SDpat_r[11] = 0x00;        //  "0"
							SDpat_r[12] = 0x00;        //  "0"
							SDpat_r[13] = 0x00;        //  "0"
							SDpat_r[14] = 0x00;        //  "0"
						}
					}else	{
						SDpat_r[5] = 0x00;         //  "0"
						SDpat_r[6] = 0x00;         //  "0"
						SDpat_r[7] = 0x00;         //  "0"
						SDpat_r[8] = 0x00;         //  "0"
						SDpat_r[9] = 0x00;         //  "0"
						SDpat_r[10] = 0x00;        //  "0"
						SDpat_r[11] = 0x00;        //  "0"
						SDpat_r[12] = 0x00;        //  "0"
						SDpat_r[13] = 0x00;        //  "0"
						SDpat_r[14] = 0x00;        //  "0"
					}
				}else	{
					SDpat_r[1] = 0x00;				 //  "0"
					SDpat_r[2] = 0x00;				 //  "0"
					SDpat_r[3] = 0x00;				 //  "0"
					SDpat_r[4] = 0x00;				 //  "0"
					SDpat_r[5] = 0x00;         //  "0"
					SDpat_r[6] = 0x00;         //  "0"
					SDpat_r[7] = 0x00;         //  "0"
					SDpat_r[8] = 0x00;         //  "0"
					SDpat_r[9] = 0x00;         //  "0"
					SDpat_r[10] = 0x00;        //  "0"
					SDpat_r[11] = 0x00;        //  "0"
					SDpat_r[12] = 0x00;        //  "0"
					SDpat_r[13] = 0x00;        //  "0"
					SDpat_r[14] = 0x00;        //  "0"
				}

				f_cnt = 0;
				res = scan_files(SDpat_r);

				for (int fi_cnt =0 ; fi_cnt< f_cnt ; fi_cnt++)	{
//						strcpy ( file , file_arr[fi_cnt]);
					file[0]= file_arr[fi_cnt][0];file[1]= file_arr[fi_cnt][1];file[2]= file_arr[fi_cnt][2];file[3]= file_arr[fi_cnt][3];
					file[4]= file_arr[fi_cnt][4];file[5]= file_arr[fi_cnt][5];file[6]= file_arr[fi_cnt][6];file[7]= file_arr[fi_cnt][7];
					r_file_name();
					rd_file ();
				}
				htim10.Init.Period = 9999;
				HAL_TIM_Base_Init(&htim10);
				HAL_TIM_Base_Start_IT(&htim10);																		//timer start blink G led
				f1.file_end = 1;	                   //read file end
				f1.history = 0;
			}
			if (pc.CommandType == 0x05)	{																						//watchdog test
				f1.error_handler = 1;
			}
//---------------------------------
			if (pc.CommandType == 0x06)	{																						//data dump enable
				f1.data_dump_flg = 0;
			}
//---------------------------------
			if (pc.CommandType == 0x07)	{																						//data dump disable
				f1.data_dump_flg = 1;
			}
		}
		f1.PC_DAT_RCV = 0;
	}
//PC Request-----------------------------------------------------------------------------------------

//watchdog refresh-----------------------------------------------------------------------------------------
		if ( f1.error_handler == 0 )  {     // no error & fault
		}
//watchdog refresh-----------------------------------------------------------------------------------------
}
  /* USER CODE END 3 */

void SystemClock_Config(void)
{
  RCC_OscInitTypeDef RCC_OscInitStruct = {0};
  RCC_ClkInitTypeDef RCC_ClkInitStruct = {0};

  /** Configure the main internal regulator output voltage
  */
  __HAL_RCC_PWR_CLK_ENABLE();
  __HAL_PWR_VOLTAGESCALING_CONFIG(PWR_REGULATOR_VOLTAGE_SCALE1);

  /** Initializes the RCC Oscillators according to the specified parameters
  * in the RCC_OscInitTypeDef structure.
  */
  RCC_OscInitStruct.OscillatorType = RCC_OSCILLATORTYPE_HSE|RCC_OSCILLATORTYPE_LSE;
  RCC_OscInitStruct.HSEState = RCC_HSE_ON;
  RCC_OscInitStruct.LSEState = RCC_LSE_ON;
  RCC_OscInitStruct.PLL.PLLState = RCC_PLL_ON;
  RCC_OscInitStruct.PLL.PLLSource = RCC_PLLSOURCE_HSE;
  RCC_OscInitStruct.PLL.PLLM = 4;
  RCC_OscInitStruct.PLL.PLLN = 168;
  RCC_OscInitStruct.PLL.PLLP = RCC_PLLP_DIV2;
  RCC_OscInitStruct.PLL.PLLQ = 7;
  if (HAL_RCC_OscConfig(&RCC_OscInitStruct) != HAL_OK)
  {
    Error_Handler();
  }

  /** Initializes the CPU, AHB and APB buses clocks
  */
  RCC_ClkInitStruct.ClockType = RCC_CLOCKTYPE_HCLK|RCC_CLOCKTYPE_SYSCLK
                              |RCC_CLOCKTYPE_PCLK1|RCC_CLOCKTYPE_PCLK2;
  RCC_ClkInitStruct.SYSCLKSource = RCC_SYSCLKSOURCE_PLLCLK;
  RCC_ClkInitStruct.AHBCLKDivider = RCC_SYSCLK_DIV1;
  RCC_ClkInitStruct.APB1CLKDivider = RCC_HCLK_DIV4;
  RCC_ClkInitStruct.APB2CLKDivider = RCC_HCLK_DIV2;

  if (HAL_RCC_ClockConfig(&RCC_ClkInitStruct, FLASH_LATENCY_5) != HAL_OK)
  {
    Error_Handler();
  }
}

/* USER CODE BEGIN 4 */
void make_folder(void)
{
	uint16_t ttt;
	SDpat[0] = 0x2F;        //  "/"
	SDpat[1] = str_table[((currentDate.Year + 2000)/1000)];
	ttt = currentDate.Year + 2000;
	ttt %= 1000;
	SDpat[2] = str_table[(ttt /100)];
	ttt %= 100;
	SDpat[3] = str_table[(ttt /10)];
	SDpat[4] = str_table[(ttt %10)];
	SDpat[5] = 0x00;				//	"0"
	res = f_mkdir ((TCHAR const*)SDpat);
	if( res != FR_OK )	{
		if ( res != FR_EXIST )  {
			Error_Handler();
		}
	}
	SDpat[5] = 0x2F;        //  "/"
	SDpat[6] = str_table[( currentDate.Month/10 )];
	SDpat[7] = str_table[( currentDate.Month %10 )];
	SDpat[8] = 0x00;				//	"0"
	res = f_mkdir ((TCHAR const*)SDpat);
	if( res != FR_OK )	{
		if ( res != FR_EXIST )  {
			Error_Handler();
		}
	}
	SDpat[8] = 0x2F;        //  "/"
	SDpat[9] = str_table[( currentDate.Date /10 )];
	SDpat[10] = str_table[( currentDate.Date %10 )];
	SDpat[11] = 0x00;				//	"0"
	res = f_mkdir ((TCHAR const*)SDpat);
	if( res != FR_OK )	{
		if ( res != FR_EXIST )  {
			Error_Handler();
		}
	}
	SDpat[11] = 0x2F;        //  "/"
	SDpat[12] = str_table[( currentTime.Hours /10 )];
	SDpat[13] = str_table[( currentTime.Hours %10 )];
	SDpat[14] = 0x00;				//	"0"
	res = f_mkdir ((TCHAR const*)SDpat);
	if( res != FR_OK )	{
		if ( res != FR_EXIST )  {
			Error_Handler();
		}
	}
}
//-------------------------------------------------------write file name provide
//mSD----------------------------------------------------------------------------
void w_file_name (void)
{
//	uint16_t ttt;
//	SDpat[0] = 0x2F;        //  "/"
//	SDpat[1] = str_table[((calendar.w_year)/1000)];
//	ttt = calendar.w_year;
//	ttt %= 1000;
//	SDpat[2] = str_table[(ttt /100)];
//	ttt %= 100;
//	SDpat[3] = str_table[(ttt /10)];
//	SDpat[4] = str_table[(ttt %10)];
//	SDpat[5] = 0x2F;        //  "/"
//	SDpat[6] = str_table[( calendar.w_month/10 )];
//	SDpat[7] = str_table[( calendar.w_month%10 )];
//	SDpat[8] = 0x2F;        //  "/"
//	SDpat[9] = str_table[( calendar.w_date /10 )];
//	SDpat[10] = str_table[( calendar.w_date %10 )];
//	SDpat[11] = 0x2F;        //  "/"
//	SDpat[12] = str_table[( calendar.hour /10 )];
//	SDpat[13] = str_table[( calendar.hour %10 )];

		NFILE[0] = SDpat[0];			//					FOLDER
		NFILE[1] = SDpat[1];
		NFILE[2] = SDpat[2];
		NFILE[3] = SDpat[3];
		NFILE[4] = SDpat[4];
		NFILE[5] = SDpat[5];
		NFILE[6] = SDpat[6];
		NFILE[7] = SDpat[7];
		NFILE[8] = SDpat[8];
		NFILE[9] = SDpat[9];
		NFILE[10] = SDpat[10];
		NFILE[11] = SDpat[11];
		NFILE[12] = SDpat[12];
		NFILE[13] = SDpat[13];

		NFILE[14] = 0x2F;         //  "/"

		NFILE[15] = SDpat[3];		  //	year		FILE
		NFILE[16] = SDpat[4];

		NFILE[17] = SDpat[6];		  //	month
		NFILE[18] = SDpat[7];

		NFILE[19] = SDpat[9];		  //	date
		NFILE[20] = SDpat[10];

		NFILE[21] = SDpat[12];	  //	hour
		NFILE[22] = SDpat[13];
		NFILE[23] = str_table[16];//	"."
		NFILE[24] = str_table[17];//	"B"
		NFILE[25] = str_table[18];//	"I"
		NFILE[26] = str_table[19];//	"N"
		NFILE[27] = 0x00;				  //	"0"
}

//-------------------------------------------------------write file name provide
void r_file_name (void)
{
	rfile[0] = 0x2F;       		   //  "/"
	rfile[1] = str_table[2];		 //  "2"
	rfile[2] = str_table[0];		 //	 "0"
	rfile[3] = file[0];
	rfile[4] = file[1];
	rfile[5] = 0x2F;        		 //  "/"
	rfile[6] = file[2];
	rfile[7] = file[3];
	rfile[8] = 0x2F;        		 //  "/"
	rfile[9] = file[4];
	rfile[10] = file[5];
	rfile[11] = 0x2F;       		 //  "/"
	rfile[12] = file[6];
	rfile[13] = file[7];

		rfile[14] = 0x2F;        	 //  "/"

		rfile[15] = file[0];		 	 //	 year		FILE
		rfile[16] = file[1];

		rfile[17] = file[2];		 	 //	 month
		rfile[18] = file[3];

		rfile[19] = file[4];		   //	 date
		rfile[20] = file[5];

		rfile[21] = file[6];	  	 //	 hour
		rfile[22] = file[7];
		rfile[23] = str_table[16]; //  "."
		rfile[24] = str_table[17]; //	 "B"
		rfile[25] = str_table[18]; //	 "I"
		rfile[26] = str_table[19]; //	 "N"
		rfile[27] = 0x00;				   //	 "0"
}

//-------------------------------------------------------dir1
FRESULT scan_files (
    char* path        /* Start node to be scanned (***also used as work area***) */
)
{
    FRESULT res;
    DIR dir;
    UINT i;
    static FILINFO fno;

    res = f_opendir(&dir, path);                      		 /* Open the directory */
    if (res == FR_OK) {
        for (;;) {
            res = f_readdir(&dir, &fno);                   /* Read a directory item */
            if (res != FR_OK || fno.fname[0] == 0) break;  /* Break on error or end of dir */
						if (fno.fname[0] == '.') continue;             /* Ignore dot entry */
						if (fno.fattrib & AM_DIR) {                    /* It is a directory */
                i = strlen(path);
                sprintf(&path[i], "/%s", fno.fname);
                res = scan_files(path);                    /* Enter the directory */
                if (res != FR_OK) break;
                path[i] = 0;
            } else {                                       /* It is a file. */
//                sprintf(file,"%s/%s\0", path, fno.fname);
								file[0]=fno.fname[0];file[1]=fno.fname[1];file[2]=fno.fname[2];file[3]=fno.fname[3];
								file[4]=fno.fname[4];file[5]=fno.fname[5];file[6]=fno.fname[6];file[7]=fno.fname[7];
//								strcpy(file_arr[f_cnt],file);
								file_arr[f_cnt][0]= file[0];file_arr[f_cnt][1]= file[1];file_arr[f_cnt][2]= file[2];file_arr[f_cnt][3]= file[3];
								file_arr[f_cnt][4]= file[4];file_arr[f_cnt][5]= file[5];file_arr[f_cnt][6]= file[6];file_arr[f_cnt][7]= file[7];
								f_cnt++;
            }
        }
        f_closedir(&dir);
    }

    return res;
}

//-------------------------------------------------------rd_file
	void rd_file (void)
	{
		f1.STM_DAT_STP = 1;
		if (f_close(&SDFile1) != FR_OK )	{																		//close writing file
			Error_Handler();
		}
		icnt = 0;
//-----
		res = f_open(&SDFile2, rfile, FA_READ);
		if (res != FR_OK)	{
			Error_Handler();
		}
		file_size = f_size(&SDFile2);
		for ( ;; )	{																			//loop for entire data read & transmit
			if ( file_size == 0 )	 {												// if size of file zero break in loop 99/07/16
				break;
			}
				diff_dat = file_size - icnt;
				if ( diff_dat > rd_step ) {
						if (f_lseek(&SDFile2, icnt)!= FR_OK)	{
							Error_Handler();
						}
						res = f_read(&SDFile2, rtext, rd_step, (UINT*)&bytesread );
						if((bytesread == 0) || (res != FR_OK)) {
							Error_Handler();
						}
						icnt += rd_step;
						CDC_Transmit_HS(rtext,rd_step);
						HAL_Delay(60);

				}else if( diff_dat == rd_step ) {
						if (f_lseek(&SDFile2, icnt)!= FR_OK)	{
							Error_Handler();
						}
						res = f_read(&SDFile2, rtext, rd_step, (UINT*)&bytesread );
						if((bytesread == 0) || (res != FR_OK)) {
							Error_Handler();
						}
						icnt += rd_step;
						CDC_Transmit_HS(rtext,rd_step);
						HAL_Delay(60);
						break;

				}else  {
						if (f_lseek(&SDFile2, icnt)!= FR_OK)	{
							Error_Handler();
						}

						res = f_read(&SDFile2, rtext, diff_dat, (UINT*)&bytesread );
						if((bytesread == 0) || (res != FR_OK)) {
							Error_Handler();
						}
						icnt += diff_dat;
						CDC_Transmit_HS(rtext,diff_dat);
						HAL_Delay(60);
						break;
				}
		}

		if (f_close(&SDFile2) != FR_OK )	{
			Error_Handler();
		}
//-----
		if (f_open(&SDFile1, NFILE, FA_OPEN_EXISTING | FA_WRITE ) != FR_OK) {	//open writing file
			Error_Handler();
		}

		if (f_lseek(&SDFile1, f_size(&SDFile1))!= FR_OK)	{
			Error_Handler();
		}
		f1.STM_DAT_STP = 0;
	}

//-----------------------------------------------------------------copy "pc_buff" to "pc structure"--------------------------------------------------------
	void cpypc_pcbuf (void)
	{
				pc.start = pc_buf[0];
				pc.CommandType = pc_buf[1];    //command : "charge = 1","shock = 2 ","sync_shock = 3 ",...
				pc.status = pc_buf[2];         //PC internal status
				pc.year = pc_buf[3];           // year (binary), offset=2000
				pc.month = pc_buf[4];          // month (binary)
				pc.day = pc_buf[5];            // day (binary)
				pc.hour = pc_buf[6];           // hour (binary)
				pc.minute = pc_buf[7];         // minute (binary)
				pc.second = pc_buf[8];         // second (binary)
				pc.stop = pc_buf[9];
	}

//mSD----------------------------------------------------------------------------
//---------------------------------------------------------------TIMER--------------------------------------------
	void HAL_TIM_PeriodElapsedCallback(TIM_HandleTypeDef *htim)
	{
		if 						(htim->Instance == TIM7)  {
			__NOP();
		}
		else if 			(htim->Instance == TIM8)  {
			__NOP();
		}
		else if 			(htim->Instance == TIM10)  {
		f1.tim10_flg = 1;
	  HAL_GPIO_TogglePin(GPIOG, GPIO_PIN_13 );
	  HAL_RTC_GetTime(&hrtc, &currentTime, FORMAT_BIN);
	  HAL_RTC_GetDate(&hrtc, &currentDate, FORMAT_BIN);
		s1.date_year = currentDate.Year + 2000 ;
		s1.date_month = currentDate.Month ;
	  s1.date_day = currentDate.Date ;
	  s1.time_hour = currentTime.Hours ;
		s1.time_minute = currentTime.Minutes ;
	  s1.time_second = currentTime.Seconds ;
    var_printH(s1.date_year,4,11,100,242);
    var_printH(s1.date_month,2,11,100,198);
    var_printH(s1.date_day,2,11,100,176);
    var_printH(s1.time_hour,2,11,100,154);
    var_printH(s1.time_minute,2,11,100,132);
    var_printH(s1.time_second,2,11,100,110);
		}
		else if 			(htim->Instance == TIM11)  {
				f1.tim11_flg = 1;
//				HAL_GPIO_TogglePin(GPIOG, GPIO_PIN_14 );
		}
		else	{
			__NOP();
		}
	}
//-----------------------------------------------------------------SPI--------------------------------------------------------
	void HAL_SPI_TxRxCpltCallback(SPI_HandleTypeDef *hspi)
	{
		if 			(hspi->Instance == SPI4)  {
			f1.spi4_strt_flg = 1;
		}
	}
//----------------------------------------------------------------EXTI----------------------------
	void HAL_GPIO_EXTI_Callback(uint16_t GPIO_Pin)
	{
		 if (GPIO_Pin == GPIO_PIN_3) {								//lcd  interrupt
				f1.data_rcv_flg = 1;
			}
	}

/* USER CODE END 4 */

void Error_Handler(void)
{
  /* USER CODE BEGIN Error_Handler_Debug */
  /* User can add his own implementation to report the HAL error return state */
  __disable_irq();
  while (1)
  {
  	HAL_GPIO_WritePin(GPIOG, GPIO_PIN_14, GPIO_PIN_SET );     //led R on
  	f1.error_handler = 1;
	}
  /* USER CODE END Error_Handler_Debug */
}
